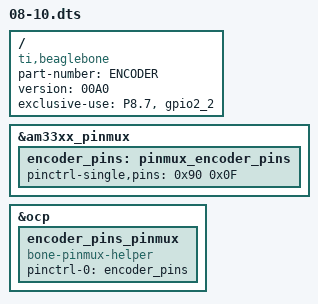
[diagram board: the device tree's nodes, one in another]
/dts-v1/;
/plugin/;

/ {
	compatible = "ti,beaglebone", "ti,beaglebone-black", "ti,beaglebone-green";

	part-number = "ENCODER";
	version = "00A0";

	exclusive-use =

		"P8.7",
		"gpio2_2";

	fragment@0 {
		target = <&am33xx_pinmux>;
		__overlay__ {
			encoder_pins: pinmux_encoder_pins {
				pinctrl-single,pins = <
					0x90 0x0F     /* P8.7 */
				>;
			};
		};
	};

	fragment@1 {
		target = <&ocp>;
		__overlay__ {
			encoder_pins_pinmux {
                	compatible = "bone-pinmux-helper";
                	status = "okay";
                	pinctrl-names = "default";
                	pinctrl-0 = <&encoder_pins>;
            		};
		};
	};

};
